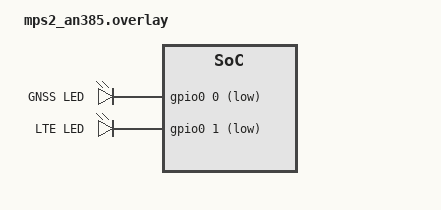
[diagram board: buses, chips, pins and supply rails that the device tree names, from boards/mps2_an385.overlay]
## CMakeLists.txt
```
cmake_minimum_required(VERSION 3.20.0)

find_package(Zephyr REQUIRED HINTS $ENV{ZEPHYR_BASE})
project(EMB-BASE-SAMPLE)

target_sources(app PRIVATE src/main.c)
```

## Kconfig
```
# Kconfig - Radar Eletrônico com Classificação
# Copyright (c) 2024, Seu Nome
# SPDX-License-Identifier: Apache-2.0

mainmenu "Radar Eletrônico com Classificação"

menu "Configurações do Radar Eletrônico"

config RADAR_SENSOR_DISTANCE_MM
    int "Distância entre os sensores em milímetros"
    range 100 2000
    default 500
    help
        Define a distância física entre os dois sensores magnéticos
        utilizados para cálculo de velocidade.
        Valor típico: 500mm (50cm)

config RADAR_SPEED_LIMIT_LIGHT_KMH
    int "Limite de velocidade para veículos leves (km/h)"
    range 40 120
    default 80
    help
        Velocidade máxima permitida para veículos leves (até 2 eixos).
        Acima deste valor é considerada infração.

config RADAR_SPEED_LIMIT_HEAVY_KMH
    int "Limite de velocidade para veículos pesados (km/h)"
    range 30 100
    default 60
    help
        Velocidade máxima permitida para veículos pesados (3+ eixos).
        Acima deste valor é considerada infração.

config RADAR_WARNING_THRESHOLD_PERCENT
    int "Percentual do limite para alerta amarelo"
    range 70 99
    default 90
    help
        Percentual do limite de velocidade que ativa o display amarelo
        de alerta. Ex: 90 = alerta ao atingir 90% do limite.

config RADAR_CAMERA_FAILURE_RATE_PERCENT
    int "Taxa de falha da câmera simulada (%)"
    range 0 100
    default 10
    help
        Porcentagem de chance da câmera simular uma falha na captura
        da placa (0-100%).

config RADAR_DEBOUNCE_TIME_MS
    int "Tempo de debounce para sensores (ms)"
    range 10 100
    default 50
    help
        Tempo mínimo entre pulsos dos sensores para evitar bouncing.
        Valor em milissegundos.

config RADAR_DISPLAY_UPDATE_INTERVAL_MS
    int "Intervalo de atualização do display (ms)"
    range 100 5000
    default 500
    help
        Intervalo entre atualizações do display virtual.
        Valor em milissegundos.

config RADAR_CAMERA_PROCESSING_TIME_MS
    int "Tempo de processamento da câmera (ms)"
    range 100 2000
    default 500
    help
        Tempo que a câmera simulada leva para processar a placa.
        Valor em milissegundos.

menu "Configurações de Log e Debug"

config RADAR_DEBUG_ENABLED
    bool "Habilitar modo debug"
    default n
    help
        Habilita mensagens de debug detalhadas no console.

config RADAR_LOG_LEVEL
    int "Nível de log do sistema"
    range 0 4
    default 2
    help
        0: Off, 1: Error, 2: Warning, 3: Info, 4: Debug

config RADAR_SENSOR_SIMULATION
    bool "Habilitar simulação de sensores"
    default y
    help
        Habilita a geração automática de eventos de sensor
        para testes sem hardware.

config RADAR_SIMULATION_INTERVAL_MS
    int "Intervalo da simulação de sensores (ms)"
    depends on RADAR_SENSOR_SIMULATION
    range 1000 10000
    default 3000
    help
        Intervalo entre eventos simulados dos sensores.
        Valor em milissegundos.

endmenu

menu "Configurações Avançadas"

config RADAR_MAX_VEHICLE_QUEUE_SIZE
    int "Tamanho máximo da fila de veículos"
    range 5 50
    default 10
    help
        Número máximo de veículos que podem estar na fila
        de processamento simultaneamente.

config RADAR_AXLE_TIMEOUT_MS
    int "Timeout para contagem de eixos (ms)"
    range 500 5000
    default 2000
    help
        Tempo máximo para considerar que um veículo passou
        completamente pelos sensores.

config RADAR_PLATE_VALIDATION_STRICT
    bool "Validação rigorosa de placas Mercosul"
    default y
    help
        Habilita validação completa do formato Mercosul
        para placas de veículos.

choice
    prompt "Estratégia de classificação de veículos"
    default RADAR_CLASSIFICATION_AXLE_COUNT

config RADAR_CLASSIFICATION_AXLE_COUNT
    bool "Classificação por contagem de eixos"
    help
        Classifica veículos baseado apenas na contagem de eixos:
        - 2 eixos: Veículo leve
        - 3+ eixos: Veículo pesado

config RADAR_CLASSIFICATION_TIME_BASED
    bool "Classificação por tempo entre eixos"
    help
        Classifica veículos baseado no tempo entre os eixos:
        - Tempo curto: Veículo pesado (mais eixos)
        - Tempo longo: Veículo leve

endchoice

config RADAR_SPEED_CALIBRATION_FACTOR
    int "Fator de calibração de velocidade"
    range 80 120
    default 100
    help
        Fator de correção para cálculo de velocidade (em porcentagem).
        Ajuste fino para compensações do sistema.

endmenu

endmenu

module = RADAR
module-str = Radar Eletrônico
source "subsys/logging/Kconfig.template.log_config"

menu "Zephyr Kernel"
source "Kconfig.zephyr"
endmenu
```

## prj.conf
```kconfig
# Configurações básicas do sistema
CONFIG_HEAP_MEM_POOL_SIZE=8192
CONFIG_MAIN_STACK_SIZE=2048
CONFIG_SYSTEM_WORKQUEUE_STACK_SIZE=2048

# GPIO
CONFIG_GPIO=y

# Display
CONFIG_DISPLAY=y
CONFIG_DISPLAY_DUMMY=y

# ZBUS
CONFIG_ZBUS=y

# Threads
CONFIG_THREAD_NAME=y

# Configurações do Radar
CONFIG_RADAR_SENSOR_DISTANCE_MM=500
CONFIG_RADAR_SPEED_LIMIT_LIGHT_KMH=80
CONFIG_RADAR_SPEED_LIMIT_HEAVY_KMH=60
CONFIG_RADAR_WARNING_THRESHOLD_PERCENT=90
CONFIG_RADAR_CAMERA_FAILURE_RATE_PERCENT=10

# Testes
CONFIG_ZTEST=y
CONFIG_TEST_LOGGING_DEFAULTS=n
```

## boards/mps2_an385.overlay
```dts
#include <zephyr/dt-bindings/gpio/gpio.h>

/ {
    aliases {
        led0 = &led0;
		led1 = &led1;
    };

    leds {
		compatible = "gpio-leds";

		led0: led0 {
			gpios = <&gpio0 0 GPIO_ACTIVE_LOW>;
			label = "GNSS LED";
		};

		led1: led1 {
			gpios = <&gpio0 1 GPIO_ACTIVE_LOW>;
			label = "LTE LED";
		};
	};
};
```

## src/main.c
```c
#include "radar.h"

void main(void)
{
    printf(COLOR_BLUE "\n=== Sistema Radar Eletronico Iniciado ===\n" COLOR_NORMAL);
    printf("Distancia entre sensores: %d mm\n", SENSOR_DISTANCE_MM);
    printf("Limite veiculos leves: %d km/h\n", SPEED_LIMIT_LIGHT);
    printf("Limite veiculos pesados: %d km/h\n", SPEED_LIMIT_HEAVY);
    printf("Limite de alerta: %d%%\n", WARNING_THRESHOLD);
    printf("Taxa de falha da camera: %d%%\n\n", CAMERA_FAILURE_RATE);
    
    // Threads são iniciadas automaticamente pelo Zephyr
    while (1) {
        k_sleep(K_SECONDS(10));
    }
}
```

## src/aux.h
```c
#ifndef AUX_H
#define AUX_H

/* Forward declarations de threads (K_THREAD_DEFINE) */
void sntp_client_thread(void *a, void *b, void *c);
void logger_thread(void *a, void *b, void *c);
void application_thread(void *a, void *b, void *c);

/* --- Estrutura da mensagem de tempo --- */
struct time_msg {
	uint64_t seconds;   /* segundos desde 1970-01-01 (Unix epoch) */
	uint32_t fraction;  /* fração (32-bit) conforme sntp_time.fraction */
};

#endif /* AUX_H */
```

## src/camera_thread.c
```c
#include "radar.h"

void camera_thread(void *arg1, void *arg2, void *arg3)
{
    ARG_UNUSED(arg1);
    ARG_UNUSED(arg2);
    ARG_UNUSED(arg3);

    bool trigger;
    camera_data_t camera_data;

    while (1) {
        // Aguarda trigger da câmera
        if (zbus_chan_read(&camera_trigger_chan, &trigger, K_FOREVER) == 0) {
            if (trigger) {
                printf(COLOR_BLUE "Camera: Capturando placa...\n" COLOR_NORMAL);
                
                // Simula processamento
                k_sleep(K_MSEC(500));
                
                // Simula captura da placa (com possibilidade de falha)
                simulate_license_plate(camera_data.plate, &camera_data.valid);
                camera_data.captured = true;
                
                printf(COLOR_BLUE "Camera: Placa %s capturada - %s\n" COLOR_NORMAL,
                       camera_data.plate,
                       camera_data.valid ? "Valida" : "Invalida");
                
                // Publica resultado
                zbus_chan_pub(&camera_result_chan, &camera_data, K_MSEC(250));
            }
        }
    }
}

K_THREAD_DEFINE(camera_thread_id, 2048, camera_thread, NULL, NULL, NULL, 3, 0, 0);
```

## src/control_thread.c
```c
#include "radar.h"

// Fila para dados do veículo
K_MSGQ_DEFINE(vehicle_data_queue, sizeof(vehicle_data_t), 10, 4);

void control_thread(void *arg1, void *arg2, void *arg3)
{
    ARG_UNUSED(arg1);
    ARG_UNUSED(arg2);
    ARG_UNUSED(arg3);

    vehicle_data_t vehicle_data;
    camera_data_t camera_data;
    bool camera_trigger = true;

    while (1) {
        // Aguarda dados do veículo
        if (k_msgq_get(&vehicle_data_queue, &vehicle_data, K_FOREVER) == 0) {
            
            // Calcula velocidade
            calculate_speed(&vehicle_data);
            
            // Verifica status da velocidade
            speed_status_t status = check_speed_status(vehicle_data.speed_kmh, 
                                                     vehicle_data.type);
            
            // Se for infração, aciona a câmera
            if (status == SPEED_INFRACTION) {
                printf(COLOR_RED "INFRACAO DETECTADA! " COLOR_NORMAL);
                printf("Veiculo: %s, Velocidade: %.1f km/h\n",
                       vehicle_data.type == VEHICLE_LIGHT ? "Leve" : "Pesado",
                       vehicle_data.speed_kmh);
                
                // Dispara câmera via ZBUS
                zbus_chan_pub(&camera_trigger_chan, &camera_trigger, K_MSEC(250));
                
                // Aguarda resultado da câmera
                if (zbus_chan_read(&camera_result_chan, &camera_data, K_MSEC(1000)) == 0) {
                    if (camera_data.captured) {
                        printf("Placa: %s - %s\n", 
                               camera_data.plate,
                               camera_data.valid ? "VALIDA" : "INVALIDA");
                    }
                }
            }
        }
        
        k_sleep(K_MSEC(10));
    }
}

K_THREAD_DEFINE(control_thread_id, 2048, control_thread, NULL, NULL, NULL, 5, 0, 0);
```

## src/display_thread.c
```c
#include "radar.h"

static const struct device *display_dev;

void update_display(float speed, vehicle_type_t type, speed_status_t status)
{
    const char *color;
    const char *status_text;
    int speed_limit;
    
    // Define cor e texto baseado no status
    switch (status) {
        case SPEED_NORMAL:
            color = COLOR_GREEN;
            status_text = "NORMAL";
            break;
        case SPEED_WARNING:
            color = COLOR_YELLOW;
            status_text = "ALERTA";
            break;
        case SPEED_INFRACTION:
            color = COLOR_RED;
            status_text = "INFRACAO";
            break;
        default:
            color = COLOR_NORMAL;
            status_text = "DESCONHECIDO";
    }
    
    // Define limite de velocidade
    speed_limit = (type == VEHICLE_LIGHT) ? SPEED_LIMIT_LIGHT : SPEED_LIMIT_HEAVY;
    
    // Formata saída com cores
    printf("\n" COLOR_BLUE "=== RADAR ELETRONICO ===\n" COLOR_NORMAL);
    printf("Veiculo: %s\n", type == VEHICLE_LIGHT ? "LEVE" : "PESADO");
    printf("Velocidade: " COLOR_BLUE "%.1f" COLOR_NORMAL " km/h\n", speed);
    printf("Limite: %d km/h\n", speed_limit);
    printf("Status: %s%s%s\n\n", color, status_text, COLOR_NORMAL);
}

void display_thread(void *arg1, void *arg2, void *arg3)
{
    ARG_UNUSED(arg1);
    ARG_UNUSED(arg2);
    ARG_UNUSED(arg3);

    display_dev = device_get_binding("DISPLAY_0");
    if (!display_dev) {
        printf("Display dummy não encontrado, usando console apenas\n");
    }

    vehicle_data_t vehicle_data;
    speed_status_t last_status = SPEED_NORMAL;
    
    while (1) {
        // Verifica se há novos dados (não bloqueante)
        if (k_msgq_get(&vehicle_data_queue, &vehicle_data, K_MSEC(100)) == 0) {
            speed_status_t current_status = check_speed_status(vehicle_data.speed_kmh, 
                                                             vehicle_data.type);
            
            // Atualiza display apenas se houve mudança
            if (current_status != last_status || vehicle_data.speed_kmh > 0) {
                update_display(vehicle_data.speed_kmh, vehicle_data.type, current_status);
                last_status = current_status;
            }
        }
        
        k_sleep(K_MSEC(500));
    }
}

K_THREAD_DEFINE(display_thread_id, 2048, display_thread, NULL, NULL, NULL, 4, 0, 0);
```

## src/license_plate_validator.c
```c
#include "radar.h"

bool validate_license_plate(const char *plate)
{
    // Verifica formato Mercosul: AAA1A23 ou AAA1234 (formato antigo)
    if (strlen(plate) != 7) {
        return false;
    }
    
    // Verifica letras nas posições 1-3
    for (int i = 0; i < 3; i++) {
        if (!isalpha(plate[i])) {
            return false;
        }
    }
    
    // Verifica dígitos e letra no formato novo
    if (isalpha(plate[3]) && isdigit(plate[4]) && isalpha(plate[5])) {
        // Formato novo: AAA1A23
        if (!isdigit(plate[6])) return false;
    } else if (isdigit(plate[3]) && isdigit(plate[4]) && isdigit(plate[5])) {
        // Formato antigo: AAA1234
        if (!isdigit(plate[6])) return false;
    } else {
        return false;
    }
    
    return true;
}

void simulate_license_plate(char *plate, bool *valid)
{
    // Gera placa aleatória
    const char letters[] = "ABCDEFGHIJKLMNOPQRSTUVWXYZ";
    const char digits[] = "0123456789";
    
    // Formato Mercosul (70% das vezes) ou antigo (30%)
    if (k_uptime_get_32() % 10 < 7) {
        // Formato Mercosul: AAA1A23
        for (int i = 0; i < 3; i++) {
            plate[i] = letters[k_uptime_get_32() % 26];
        }
        plate[3] = digits[k_uptime_get_32() % 10];
        plate[4] = letters[k_uptime_get_32() % 26];
        plate[5] = digits[k_uptime_get_32() % 10];
        plate[6] = digits[k_uptime_get_32() % 10];
    } else {
        // Formato antigo: AAA1234
        for (int i = 0; i < 3; i++) {
            plate[i] = letters[k_uptime_get_32() % 26];
        }
        for (int i = 3; i < 7; i++) {
            plate[i] = digits[k_uptime_get_32() % 10];
        }
    }
    plate[7] = '\0';
    
    // Simula falha baseada na taxa configurada
    *valid = ((k_uptime_get_32() % 100) >= CAMERA_FAILURE_RATE);
    
    // Se for inválida, corrompe a placa
    if (!*valid) {
        plate[2] = '0'; // Caractere inválido na posição de letra
    }
}
```

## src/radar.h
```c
#ifndef RADAR_H
#define RADAR_H

#include <zephyr.h>
#include <drivers/gpio.h>
#include <drivers/display.h>
#include <zbus.h>
#include <string.h>
#include <stdlib.h>
#include <stdio.h>
#include <ctype.h>
#include <math.h>

// Configurações via Kconfig
#define SENSOR_DISTANCE_MM          CONFIG_RADAR_SENSOR_DISTANCE_MM
#define SPEED_LIMIT_LIGHT           CONFIG_RADAR_SPEED_LIMIT_LIGHT_KMH
#define SPEED_LIMIT_HEAVY           CONFIG_RADAR_SPEED_LIMIT_HEAVY_KMH
#define WARNING_THRESHOLD           CONFIG_RADAR_WARNING_THRESHOLD_PERCENT
#define CAMERA_FAILURE_RATE         CONFIG_RADAR_CAMERA_FAILURE_RATE_PERCENT
#define DEBOUNCE_TIME_MS            CONFIG_RADAR_DEBOUNCE_TIME_MS
#define DISPLAY_UPDATE_INTERVAL_MS  CONFIG_RADAR_DISPLAY_UPDATE_INTERVAL_MS
#define CAMERA_PROCESSING_TIME_MS   CONFIG_RADAR_CAMERA_PROCESSING_TIME_MS
#define MAX_VEHICLE_QUEUE_SIZE      CONFIG_RADAR_MAX_VEHICLE_QUEUE_SIZE
#define AXLE_TIMEOUT_MS             CONFIG_RADAR_AXLE_TIMEOUT_MS
#define PLATE_VALIDATION_STRICT     CONFIG_RADAR_PLATE_VALIDATION_STRICT
#define SPEED_CALIBRATION_FACTOR    (CONFIG_RADAR_SPEED_CALIBRATION_FACTOR / 100.0f)

// Configurações de classificação
#if defined(CONFIG_RADAR_CLASSIFICATION_AXLE_COUNT)
#define CLASSIFICATION_BY_AXLE_COUNT 1
#define CLASSIFICATION_BY_TIME 0
#elif defined(CONFIG_RADAR_CLASSIFICATION_TIME_BASED)
#define CLASSIFICATION_BY_AXLE_COUNT 0
#define CLASSIFICATION_BY_TIME 1
#else
#define CLASSIFICATION_BY_AXLE_COUNT 1
#define CLASSIFICATION_BY_TIME 0
#endif

// Configurações de debug
#if defined(CONFIG_RADAR_DEBUG_ENABLED)
#define RADAR_DEBUG 1
#else
#define RADAR_DEBUG 0
#endif

#if defined(CONFIG_RADAR_SENSOR_SIMULATION)
#define SENSOR_SIMULATION 1
#define SIMULATION_INTERVAL_MS CONFIG_RADAR_SIMULATION_INTERVAL_MS
#else
#define SENSOR_SIMULATION 0
#endif

// Níveis de log
#if CONFIG_RADAR_LOG_LEVEL >= 4
#define RADAR_LOG_DEBUG 1
#else
#define RADAR_LOG_DEBUG 0
#endif

#if CONFIG_RADAR_LOG_LEVEL >= 3
#define RADAR_LOG_INFO 1
#else
#define RADAR_LOG_INFO 0
#endif

#if CONFIG_RADAR_LOG_LEVEL >= 2
#define RADAR_LOG_WARN 1
#else
#define RADAR_LOG_WARN 0
#endif

#if CONFIG_RADAR_LOG_LEVEL >= 1
#define RADAR_LOG_ERR 1
#else
#define RADAR_LOG_ERR 0
#endif

// GPIO dos sensores
#define SENSOR_1_PIN         5
#define SENSOR_2_PIN         6

// Constantes de conversão
#define MS_TO_HOURS          3.6e6f    // 1 hora = 3.600.000 ms
#define MM_TO_KM             1e-6f     // 1 mm = 0.000001 km
#define MIN_TIME_BETWEEN_SENSORS 10    // Tempo mínimo válido entre sensores (ms)

// Cores ANSI
#define COLOR_NORMAL         "\033[0m"
#define COLOR_GREEN          "\033[32m"
#define COLOR_YELLOW         "\033[33m"
#define COLOR_RED            "\033[31m"
#define COLOR_BLUE           "\033[34m"
#define COLOR_CYAN           "\033[36m"
#define COLOR_MAGENTA        "\033[35m"
#define COLOR_BRIGHT_GREEN   "\033[92m"
#define COLOR_BRIGHT_YELLOW  "\033[93m"
#define COLOR_BRIGHT_RED     "\033[91m"
#define COLOR_BRIGHT_BLUE    "\033[94m"

// Macros para logging
#define RADAR_DBG(fmt, ...) \
    do { \
        if (RADAR_DEBUG && RADAR_LOG_DEBUG) { \
            printk(COLOR_CYAN "[RADAR-DBG] %s:%d: " fmt COLOR_NORMAL "\n", \
                   __func__, __LINE__, ##__VA_ARGS__); \
        } \
    } while (0)

#define RADAR_INFO(fmt, ...) \
    do { \
        if (RADAR_LOG_INFO) { \
            printk(COLOR_BLUE "[RADAR-INFO] " fmt COLOR_NORMAL "\n", ##__VA_ARGS__); \
        } \
    } while (0)

#define RADAR_WARN(fmt, ...) \
    do { \
        if (RADAR_LOG_WARN) { \
            printk(COLOR_YELLOW "[RADAR-WARN] " fmt COLOR_NORMAL "\n", ##__VA_ARGS__); \
        } \
    } while (0)

#define RADAR_ERR(fmt, ...) \
    do { \
        if (RADAR_LOG_ERR) { \
            printk(COLOR_RED "[RADAR-ERR] " fmt COLOR_NORMAL "\n", ##__VA_ARGS__); \
        } \
    } while (0)

#define RADAR_SUCCESS(fmt, ...) \
    do { \
        if (RADAR_LOG_INFO) { \
            printk(COLOR_BRIGHT_GREEN "[RADAR] " fmt COLOR_NORMAL "\n", ##__VA_ARGS__); \
        } \
    } while (0)

// Tipos de veículo
typedef enum {
    VEHICLE_UNKNOWN = 0,
    VEHICLE_LIGHT,
    VEHICLE_HEAVY
} vehicle_type_t;

// Status de velocidade
typedef enum {
    SPEED_NORMAL = 0,
    SPEED_WARNING,
    SPEED_INFRACTION
} speed_status_t;

// Status do sistema
typedef enum {
    SYSTEM_INIT = 0,
    SYSTEM_READY,
    SYSTEM_CALIBRATING,
    SYSTEM_ERROR
} system_status_t;

// Direção do veículo
typedef enum {
    DIRECTION_UNKNOWN = 0,
    DIRECTION_FORWARD,   // Sensor1 -> Sensor2
    DIRECTION_BACKWARD   // Sensor2 -> Sensor1
} direction_t;

// Estrutura de dados do veículo
typedef struct {
    uint32_t timestamp;
    uint32_t time_between_sensors;
    vehicle_type_t type;
    float speed_kmh;
    uint8_t axle_count;
    direction_t direction;
    uint32_t total_passage_time;
    bool valid_measurement;
} vehicle_data_t;

// Estrutura de dados da câmera
typedef struct {
    char plate[8]; // AAA1A23 ou AAA1234 + null terminator
    bool valid;
    bool captured;
    uint32_t capture_time;
    vehicle_type_t vehicle_type;
    float vehicle_speed;
} camera_data_t;

// Estrutura de estatísticas do sistema
typedef struct {
    uint32_t total_vehicles;
    uint32_t light_vehicles;
    uint32_t heavy_vehicles;
    uint32_t infringements;
    uint32_t camera_failures;
    uint32_t system_errors;
} system_stats_t;

// Mensagens ZBUS
ZBUS_CHAN_DECLARE(camera_trigger_chan);
ZBUS_CHAN_DECLARE(camera_result_chan);
ZBUS_CHAN_DECLARE(system_status_chan);
ZBUS_CHAN_DECLARE(system_stats_chan);

// Estruturas ZBUS
ZBUS_CHAN_DEFINE(camera_trigger_chan,     /* Name */
                 vehicle_data_t,          /* Message type */
                 NULL,                    /* Validator */
                 NULL,                    /* User data */
                 ZBUS_OBSERVERS_EMPTY,    /* Observers */
                 ZBUS_MSG_INIT({0})       /* Initial value */
);

ZBUS_CHAN_DEFINE(camera_result_chan,      /* Name */
                 camera_data_t,           /* Message type */
                 NULL,                    /* Validator */
                 NULL,                    /* User data */
                 ZBUS_OBSERVERS_EMPTY,    /* Observers */
                 ZBUS_MSG_INIT({0})       /* Initial value */
);

ZBUS_CHAN_DEFINE(system_status_chan,      /* Name */
                 system_status_t,         /* Message type */
                 NULL,                    /* Validator */
                 NULL,                    /* User data */
                 ZBUS_OBSERVERS_EMPTY,    /* Observers */
                 ZBUS_MSG_INIT(SYSTEM_INIT) /* Initial value */
);

ZBUS_CHAN_DEFINE(system_stats_chan,       /* Name */
                 system_stats_t,          /* Message type */
                 NULL,                    /* Validator */
                 NULL,                    /* User data */
                 ZBUS_OBSERVERS_EMPTY,    /* Observers */
                 ZBUS_MSG_INIT({0})       /* Initial value */
);

// Filas de mensagens
extern struct k_msgq vehicle_data_queue;

// Semáforos e mutexes
extern struct k_sem sensor_sem;
extern struct k_mutex stats_mutex;

// Estatísticas globais do sistema
extern system_stats_t global_stats;

// Protótipos de funções públicas

// Funções de inicialização
void radar_system_init(void);
void radar_print_configuration(void);

// Funções de sensores
void sensor_interrupts_init(void);
void simulate_sensor_events(void);
bool validate_vehicle_data(const vehicle_data_t *data);

// Funções de cálculo e classificação
void calculate_speed(vehicle_data_t *vehicle);
speed_status_t check_speed_status(float speed, vehicle_type_t type);
vehicle_type_t classify_vehicle(const vehicle_data_t *data);
direction_t determine_direction(uint32_t sensor1_time, uint32_t sensor2_time);

// Funções de display
void update_display(float speed, vehicle_type_t type, speed_status_t status);
void display_system_status(system_status_t status);
void display_statistics(void);
void clear_display(void);

// Funções de câmera e placas
bool validate_license_plate(const char *plate);
void simulate_license_plate(char *plate, bool *valid);
void camera_capture_plate(const vehicle_data_t *vehicle_data);

// Funções de utilidade
uint32_t get_current_timestamp(void);
void update_system_stats(vehicle_type_t type, bool infringement, bool camera_fail);
void reset_system_stats(void);
float apply_calibration_factor(float speed);

// Funções de debug
void radar_debug_print(const char *message);
void print_vehicle_data(const vehicle_data_t *data);
void print_camera_data(const camera_data_t *data);

// Funções de teste (apenas quando em modo de teste)
#ifdef CONFIG_ZTEST
void test_calculate_speed(void);
void test_classify_vehicle(void);
void test_validate_license_plate(void);
#endif

// Funções de tratamento de erro
void handle_system_error(const char *error_message);
void recover_from_error(void);

// Constantes para validação
static const char *VEHICLE_TYPE_STR[] = {
    "DESCONHECIDO",
    "LEVE",
    "PESADO"
};

static const char *SPEED_STATUS_STR[] = {
    "NORMAL",
    "ALERTA",
    "INFRACAO"
};

static const char *DIRECTION_STR[] = {
    "DESCONHECIDA",
    "FRENTE",
    "TRAS"
};

// Inline functions para melhor performance
static inline bool is_valid_speed(float speed) {
    return (speed >= 1.0f && speed <= 300.0f); // 1-300 km/h
}

static inline bool is_valid_axle_count(uint8_t axles) {
    return (axles >= 1 && axles <= 10); // 1-10 eixos
}

static inline bool is_valid_time_between_sensors(uint32_t time_ms) {
    return (time_ms >= MIN_TIME_BETWEEN_SENSORS && time_ms <= 10000); // 10ms - 10s
}

static inline const char* get_vehicle_type_str(vehicle_type_t type) {
    if (type >= VEHICLE_UNKNOWN && type <= VEHICLE_HEAVY) {
        return VEHICLE_TYPE_STR[type];
    }
    return "INVALIDO";
}

static inline const char* get_speed_status_str(speed_status_t status) {
    if (status >= SPEED_NORMAL && status <= SPEED_INFRACTION) {
        return SPEED_STATUS_STR[status];
    }
    return "INVALIDO";
}

static inline const char* get_direction_str(direction_t direction) {
    if (direction >= DIRECTION_UNKNOWN && direction <= DIRECTION_BACKWARD) {
        return DIRECTION_STR[direction];
    }
    return "INVALIDO";
}

#endif /* RADAR_H */
```

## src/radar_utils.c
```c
#include "radar.h"

// Variáveis globais
system_stats_t global_stats = {0};
struct k_sem sensor_sem;
struct k_mutex stats_mutex;

void radar_system_init(void)
{
    // Inicializa semáforos e mutexes
    k_sem_init(&sensor_sem, 1, 1);
    k_mutex_init(&stats_mutex);
    
    // Reseta estatísticas
    reset_system_stats();
    
    // Publica status inicial
    system_status_t status = SYSTEM_READY;
    zbus_chan_pub(&system_status_chan, &status, K_MSEC(100));
    
    RADAR_SUCCESS("Sistema radar inicializado com sucesso");
}

void radar_print_configuration(void)
{
    RADAR_INFO("=== CONFIGURACAO DO RADAR ===");
    RADAR_INFO("Distancia entre sensores: %d mm", SENSOR_DISTANCE_MM);
    RADAR_INFO("Limite veiculos leves: %d km/h", SPEED_LIMIT_LIGHT);
    RADAR_INFO("Limite veiculos pesados: %d km/h", SPEED_LIMIT_HEAVY);
    RADAR_INFO("Limite de alerta: %d%%", WARNING_THRESHOLD);
    RADAR_INFO("Taxa de falha da camera: %d%%", CAMERA_FAILURE_RATE);
    RADAR_INFO("Tempo de debounce: %d ms", DEBOUNCE_TIME_MS);
    RADAR_INFO("Fator de calibracao: %.2f", SPEED_CALIBRATION_FACTOR);
    RADAR_INFO("Classificacao por: %s", 
               CLASSIFICATION_BY_AXLE_COUNT ? "CONTAGEM DE EIXOS" : "TEMPO ENTRE EIXOS");
    RADAR_INFO("Validacao rigorosa: %s", PLATE_VALIDATION_STRICT ? "SIM" : "NAO");
    RADAR_INFO("Modo debug: %s", RADAR_DEBUG ? "ATIVADO" : "DESATIVADO");
    RADAR_INFO("Simulacao: %s", SENSOR_SIMULATION ? "ATIVADA" : "DESATIVADA");
}

void update_system_stats(vehicle_type_t type, bool infringement, bool camera_fail)
{
    k_mutex_lock(&stats_mutex, K_FOREVER);
    
    global_stats.total_vehicles++;
    
    if (type == VEHICLE_LIGHT) {
        global_stats.light_vehicles++;
    } else if (type == VEHICLE_HEAVY) {
        global_stats.heavy_vehicles++;
    }
    
    if (infringement) {
        global_stats.infringements++;
    }
    
    if (camera_fail) {
        global_stats.camera_failures++;
    }
    
    // Publica estatísticas atualizadas
    zbus_chan_pub(&system_stats_chan, &global_stats, K_NO_WAIT);
    
    k_mutex_unlock(&stats_mutex);
}

void reset_system_stats(void)
{
    k_mutex_lock(&stats_mutex, K_FOREVER);
    memset(&global_stats, 0, sizeof(system_stats_t));
    k_mutex_unlock(&stats_mutex);
}

uint32_t get_current_timestamp(void)
{
    return k_uptime_get_32();
}

float apply_calibration_factor(float speed)
{
    return speed * SPEED_CALIBRATION_FACTOR;
}

void handle_system_error(const char *error_message)
{
    RADAR_ERR("Erro do sistema: %s", error_message);
    
    k_mutex_lock(&stats_mutex, K_FOREVER);
    global_stats.system_errors++;
    k_mutex_unlock(&stats_mutex);
    
    // Publica status de erro
    system_status_t status = SYSTEM_ERROR;
    zbus_chan_pub(&system_status_chan, &status, K_MSEC(100));
}

void recover_from_error(void)
{
    RADAR_WARN("Tentando recuperar do erro...");
    
    // Publica status de calibração
    system_status_t status = SYSTEM_CALIBRATING;
    zbus_chan_pub(&system_status_chan, &status, K_MSEC(100));
    
    k_sleep(K_SECONDS(2));
    
    // Volta para ready
    status = SYSTEM_READY;
    zbus_chan_pub(&system_status_chan, &status, K_MSEC(100));
    
    RADAR_SUCCESS("Sistema recuperado com sucesso");
}
```

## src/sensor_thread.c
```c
#include "radar.h"

static const struct device *gpio_dev;
static struct gpio_callback sensor1_cb, sensor2_cb;

// Variáveis para máquina de estados
static volatile uint32_t sensor1_time = 0;
static volatile uint32_t sensor2_time = 0;
static volatile uint8_t axle_count = 0;
static volatile uint32_t last_axle_time = 0;
static volatile bool sensor1_triggered = false;

// Interrupção do Sensor 1 (contagem de eixos)
void sensor1_handler(const struct device *dev, struct gpio_callback *cb, uint32_t pins)
{
    uint32_t current_time = k_uptime_get_32();
    
    // Filtro de bouncing (mínimo 50ms entre pulsos)
    if ((current_time - last_axle_time) > 50) {
        axle_count++;
        last_axle_time = current_time;
    }
    
    sensor1_triggered = true;
    sensor1_time = current_time;
}

// Interrupção do Sensor 2 (cálculo de velocidade)
void sensor2_handler(const struct device *dev, struct gpio_callback *cb, uint32_t pins)
{
    if (sensor1_triggered) {
        sensor2_time = k_uptime_get_32();
        
        // Prepara dados do veículo
        vehicle_data_t vehicle_data = {
            .timestamp = k_uptime_get_32(),
            .time_between_sensors = sensor2_time - sensor1_time,
            .axle_count = axle_count
        };
        
        // Classifica veículo baseado no número de eixos
        if (axle_count >= 3) {
            vehicle_data.type = VEHICLE_HEAVY;
        } else if (axle_count == 2) {
            vehicle_data.type = VEHICLE_LIGHT;
        } else {
            vehicle_data.type = VEHICLE_UNKNOWN;
        }
        
        // Envia dados para a thread de controle
        k_msgq_put(&vehicle_data_queue, &vehicle_data, K_NO_WAIT);
        
        // Reseta contadores
        axle_count = 0;
        sensor1_triggered = false;
    }
}

void sensor_thread(void *arg1, void *arg2, void *arg3)
{
    ARG_UNUSED(arg1);
    ARG_UNUSED(arg2);
    ARG_UNUSED(arg3);

    gpio_dev = device_get_binding("GPIO_0");
    if (!gpio_dev) {
        printf("Erro: GPIO device not found\n");
        return;
    }

    // Configura Sensor 1 (contagem de eixos)
    gpio_pin_configure(gpio_dev, SENSOR_1_PIN, 
                      GPIO_INPUT | GPIO_PULL_UP | GPIO_INT_EDGE_FALLING);
    gpio_init_callback(&sensor1_cb, sensor1_handler, BIT(SENSOR_1_PIN));
    gpio_add_callback(gpio_dev, &sensor1_cb);
    gpio_pin_interrupt_configure(gpio_dev, SENSOR_1_PIN, GPIO_INT_EDGE_FALLING);

    // Configura Sensor 2 (velocidade)
    gpio_pin_configure(gpio_dev, SENSOR_2_PIN, 
                      GPIO_INPUT | GPIO_PULL_UP | GPIO_INT_EDGE_FALLING);
    gpio_init_callback(&sensor2_cb, sensor2_handler, BIT(SENSOR_2_PIN));
    gpio_add_callback(gpio_dev, &sensor2_cb);
    gpio_pin_interrupt_configure(gpio_dev, SENSOR_2_PIN, GPIO_INT_EDGE_FALLING);

    printf("Sensores inicializados - GPIO %d (eixos) e GPIO %d (velocidade)\n", 
           SENSOR_1_PIN, SENSOR_2_PIN);

    while (1) {
        k_sleep(K_SECONDS(1));
    }
}

K_THREAD_DEFINE(sensor_thread_id, 2048, sensor_thread, NULL, NULL, NULL, 6, 0, 0);
```

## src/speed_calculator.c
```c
#include "radar.h"

void calculate_speed(vehicle_data_t *vehicle)
{
    if (vehicle->time_between_sensors == 0) {
        vehicle->speed_kmh = 0.0f;
        return;
    }
    
    // Calcula velocidade em km/h
    // distância em metros / tempo em horas
    float distance_m = SENSOR_DISTANCE_MM / 1000.0f;
    float time_h = vehicle->time_between_sensors / 3600000.0f; // ms para horas
    
    vehicle->speed_kmh = distance_m / 1000.0f / time_h; // m/s para km/h
}

speed_status_t check_speed_status(float speed, vehicle_type_t type)
{
    int speed_limit = (type == VEHICLE_LIGHT) ? SPEED_LIMIT_LIGHT : SPEED_LIMIT_HEAVY;
    float warning_threshold = speed_limit * (WARNING_THRESHOLD / 100.0f);
    
    if (speed > speed_limit) {
        return SPEED_INFRACTION;
    } else if (speed > warning_threshold) {
        return SPEED_WARNING;
    } else {
        return SPEED_NORMAL;
    }
}
```
